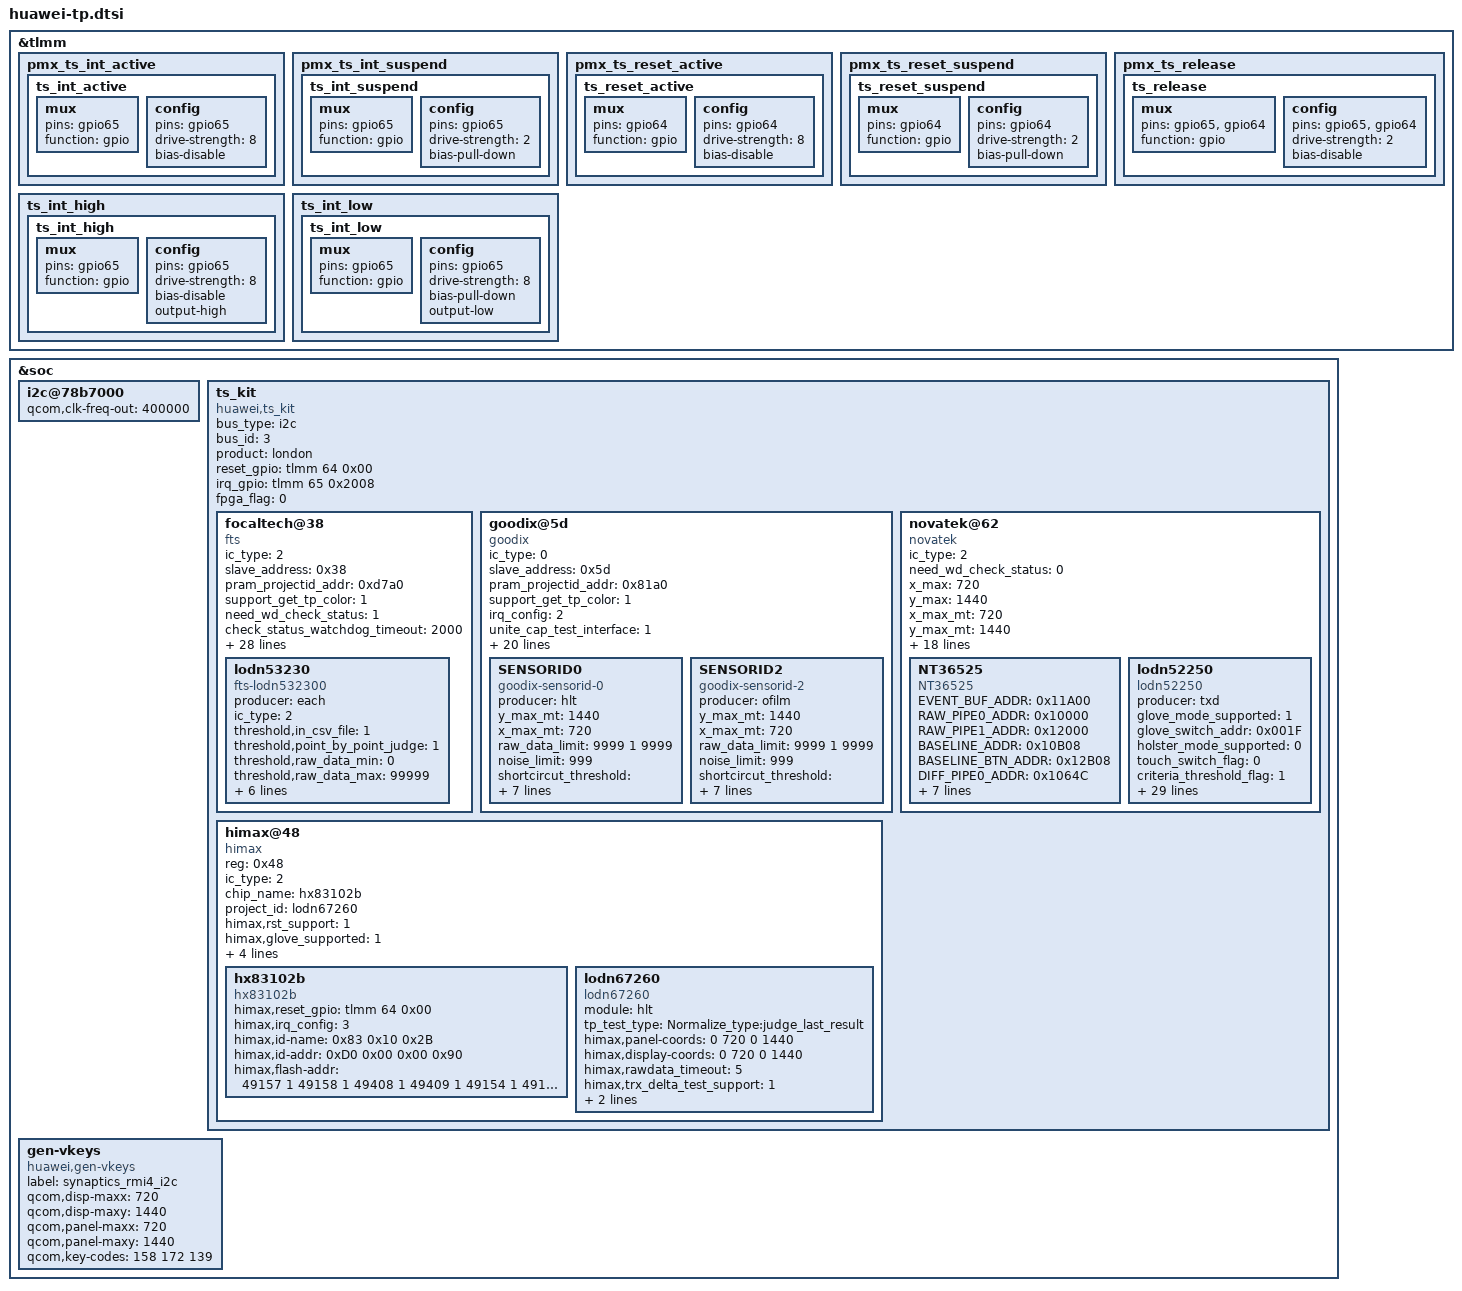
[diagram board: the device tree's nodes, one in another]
/* touch panel config */
&tlmm {
		/* add pingrp for touchscreen */
		pmx_ts_int_active {
			ts_int_active: ts_int_active {
				mux {
					pins = "gpio65";
					function = "gpio";
				};

				config {
					pins = "gpio65";
					drive-strength = <8>;
					bias-disable;
				};
			};
		};

		pmx_ts_int_suspend {
			ts_int_suspend: ts_int_suspend {
				mux {
					pins = "gpio65";
					function = "gpio";
				};

				config {
					pins = "gpio65";
					drive-strength = <2>;
					bias-pull-down;
				};
			};
		};

		pmx_ts_reset_active {
			ts_reset_active: ts_reset_active {
				mux {
					pins = "gpio64";
					function = "gpio";
				};

				config {
					pins = "gpio64";
					drive-strength = <8>;
					bias-disable;
				};
			};
		};

		pmx_ts_reset_suspend {
			ts_reset_suspend: ts_reset_suspend {
				mux {
					pins = "gpio64";
					function = "gpio";
				};

				config {
					pins = "gpio64";
					drive-strength = <2>;
					bias-pull-down;
				};
			};
		};

		pmx_ts_release {
			ts_release: ts_release {
				mux {
					pins = "gpio65", "gpio64";
					function = "gpio";
				};

				config {
					pins = "gpio65", "gpio64";
					drive-strength = <2>;
					bias-disable;
				};
			};
		};
		ts_int_high {
			ts_int_high: ts_int_high {
				mux {
					pins = "gpio65";
					function = "gpio";
				};

				config {
					pins = "gpio65";
					drive-strength = <8>;
					bias-disable;
					output-high;
				};
			};
		};
		ts_int_low {
			ts_int_low: ts_int_low {
				mux {
					pins = "gpio65";
					function = "gpio";
				};

				config {
					pins = "gpio65";
					drive-strength = <8>;
					bias-pull-down;
					output-low;
				};
			};
		};
};

&soc {
	i2c@78b7000{
		status = "ok";
		#address-cells = <1>;
		#size-cells = <0>;
		qcom,clk-freq-out = <400000>;
	};
	ts_kit {
		#address-cells = <1>;
		#size-cells = <0>;
		compatible = "huawei,ts_kit";
		bus_type = "i2c";
		bus_id = <3>;
		product = "london";
		reset_gpio = <&tlmm 64 0x00>;
		irq_gpio = <&tlmm 65 0x2008>;
		fpga_flag = <0>;
		focaltech@38 {
			compatible = "fts";
			ic_type = <2>;
			slave_address = <0x38>;
			pram_projectid_addr = <0xd7a0>;
			support_get_tp_color = <1>;
			need_wd_check_status = <1>;
			check_status_watchdog_timeout = <2000>;
			x_max = <720>;
			y_max = <1440>;
			x_max_mt = <720>;
			y_max_mt = <1440>;
			unite_cap_test_interface =<1>;
			report_rate_test =<0>;
			vci_gpio_type = <0>;
			vci_regulator_type = <1>;
			vddio_gpio_type = <0>;
			vddio_regulator_type = <1>;
			chip_id = <0x87>;
			hard_reset_delay = <200>;
			erase_min_delay = <1350>;
			calc_crc_delay = <300>;
			reboot_delay = <300>;
			erase_query_delay = <50>;
			write_flash_query_times = <30>;
			read_ecc_query_times = <100>;
			erase_flash_query_times = <15>;
			upgrade_loop_times = <5>;
			glove_supported = <1>;
			glove_switch_addr = <0xC0>;
			holster_switch_addr = <0xC1>;
			gesture_supported = <1>;
			irq_config = <3>;
			algo_id = <1>;
			is_in_cell = <0>;
			only_open_once_captest_threshold = <1>;
			lodn53230 {
				producer = "each";
				ic_type = <2>;
				compatible = "fts-lodn532300";
				threshold,in_csv_file = <1>;
				threshold,point_by_point_judge = <1>;
				threshold,raw_data_min = <0>;
				threshold,raw_data_max = <99999>;
				threshold,cb_test_min = <0>;
				threshold,cb_test_max = <9999>;
				threshold,scap_raw_data_min = <0>;
				threshold,scap_raw_data_max = <90000>;
				threshold,short_circuit_min = <0>;
				//threshold,open_test_cb_min = <100>;
				threshold,lcd_noise_max = <100>;
			};

		};
		goodix@5d {
			compatible = "goodix";
			ic_type = <0>;
			slave_address = <0x5d>;
			pram_projectid_addr = <0x81a0>;
			support_get_tp_color = <1>;
			irq_config = <2>;
			unite_cap_test_interface =<1>;
			algo_id = <2>;
			x_max = <720>;
			y_max = <1440>;
			x_max_mt = <720>;
			y_max_mt = <1440>;
			product_id = "GT917D";
			tools_support;
			huawei,test_capacitance_via_csvfile = <1>;
			huawei,csvfile_use_product_system = <1>;
			only_open_once_captest_threshold = <1>;
			need_wd_check_status = <1>;
			check_status_watchdog_timeout = <2000>;
			roi_data_size = <7 7>;
			gesture_supported = <1>;
			tp_test_type = "Normalize_type:judge_last_result";
			pinctrl-names = "pmx_ts_active","pmx_ts_suspend","pmx_ts_release","ts_int_high","ts_int_low";
			pinctrl-0 = <&ts_int_active &ts_reset_active>;
			pinctrl-1 = <&ts_int_suspend &ts_reset_suspend>;
			pinctrl-2 = <&ts_release>;
			pinctrl-3 = <&ts_int_high>;
			pinctrl-4 = <&ts_int_low>;
			SENSORID0 {
				compatible = "goodix-sensorid-0";
				producer = "hlt";
				y_max_mt = <1440>;
				x_max_mt = <720>;
				raw_data_limit = <9999 1 9999>;     /*rawdata-max*/
				noise_limit = <999>;
				shortcircut_threshold = <10 100 100 100 150 150 28>;
				normal_config = [
				4E D0 02 A0 05 0A FC 32 11 8F 2F
				0F 5F 4B 03 05 00 00 60 62 01 12
				05 16 19 1F 14 C7 27 EE 3C 3E B8
				08 B8 08 00 C3 33 91 00 00 00 00
				00 02 C0 08 0A 00 1A 28 50 8A 90
				54 19 28 00 04 AA 2A 00 97 31 00
				8A 38 00 7E 41 00 75 4A 00 75 00
				00 00 00 00 00 00 00 00 00 46 43
				00 00 00 00 00 00 00 02 00 00 0F
				32 00 03 00 00 32 05 55 00 00 00
				00 41 0D 00 01 02 03 04 05 06 07
				08 09 0A 0B 0C 1B 1A 19 18 17 16
				15 14 13 12 11 10 0F 0E FF FF 00
				02 04 05 06 08 0A 1E 1F 20 22 24
				29 2A FF FF FF 8C 31 3C 3C 00 8C
				70 12 00 32 4B 5A 19 1E 3C 0F 00
				06 66 66 0F 10 8B 84 85 00 00 00
				00 00 00 00 00 00 00 00 00 32 2D
				00 00 0F 14 00 37 5A 00 78 78 95
				00 55 00 41 43 E0 00 5A 32 08 00
				1E 03 00 00 00 00 1F 01];

				glove_config = [];
				holster_config = [];
				tptest_config = [
				00 D0 02 A0 05 05 3C 48 01 08
				28 0F 5A 46 05 05 00 00 00 00
				00 00 00 17 19 1E 14 87 27 EE
				96 98 D3 07 00 00 00 B9 32 11
				00 00 00 00 00 03 00 10 C8 00
				43 1E 50 94 10 03 07 28 00 04
				A3 21 00 8A 28 00 74 31 00 64
				3B 00 55 48 00 56 00 00 00 00
				00 00 00 00 00 00 00 00 00 00
				00 00 00 00 FF 7F 00 55 00 00
				00 00 00 00 00 01 46 00 00 00
				00 32 0D 00 01 02 03 04 05 06
				07 08 09 0A 0B 0C 1B 1A 19 18
				17 16 15 14 13 12 11 10 0F 0E
				FF FF 00 02 04 05 06 08 0A 1E
				1F 20 22 24 29 2A FF FF FF 00
				00 00 00 00 00 00 00 00 00 00
				00 00 00 00 00 00 00 00 00 00
				00 00 00 00 00 00 00 00 00 00
				00 00 00 00 00 00 00 00 00 00
				00 00 00 00 00 00 00 00 00 00
				00 00 00 00 00 00 00 00 00 00
				00 00 00 00 00 00 27 01];
			};
                        SENSORID2 {
				compatible = "goodix-sensorid-2";
				producer = "ofilm";
				y_max_mt = <1440>;
				x_max_mt = <720>;
				raw_data_limit = <9999 1 9999>;     /*rawdata-max*/
				noise_limit = <999>;
				shortcircut_threshold = <10 100 100 100 150 150 28>;
				normal_config = [
				4E D0 02 A0 05 0A FC 32 11 8F 2F
				0F 5F 50 03 05 00 00 60 62 02 01
				05 16 19 1F 14 C7 27 EE 3E 40 B8
				08 B8 08 00 C3 23 91 00 00 00 00
				00 02 C0 08 0A 00 1B 28 50 8A 90
				64 19 28 00 04 A9 2A 00 96 31 00
				89 38 00 7C 41 00 72 4A 00 72 00
				00 00 00 00 00 00 00 00 00 46 03
				00 00 00 00 00 00 00 02 00 00 0F
				32 00 03 00 00 32 06 4B 00 00 00
				00 41 04 13 00 1B 1A 19 18 17 16
				15 14 01 02 03 10 0F 0E 0D 0C 11
				12 0B 0A 09 08 07 06 05 FF FF 00
				02 04 05 06 08 0A 1E 1F 20 22 24
				29 2A FF FF FF 8C 31 3C 3C 00 8C
				70 12 00 32 4B 5A 19 1E 4B 00 00
				06 66 66 0F 10 8B 84 85 00 00 00
				00 00 00 00 00 00 00 00 00 32 28
				00 00 0F 14 00 37 53 00 78 78 95
				00 55 00 3C 43 E0 00 5A 32 08 00
				1E 03 00 00 00 00 8A 01];

				glove_config = [];
				holster_config = [];
				tptest_config = [
				00 D0 02 A0 05 0A 08 00 01 0F
				28 0F 82 64 03 05 00 00 00 00
				00 00 00 00 00 00 00 87 27 EE
				4C 4E D9 0B 00 00 00 01 03 1D
				00 00 00 00 00 00 00 00 00 00
				00 00 00 00 00 00 00 00 00 00
				00 00 00 00 00 00 00 00 00 00
				00 00 00 00 00 00 00 00 00 00
				00 00 00 00 00 00 00 00 00 00
				00 00 00 00 00 00 00 00 00 00
				00 00 00 00 00 00 00 00 00 00
				00 00 04 13 00 1B 1A 19 18 17
				16 15 14 01 02 03 10 0F 0E 0D
				0C 11 12 0B 0A 09 08 07 06 05
				FF FF 00 02 04 05 06 08 0A 1E
				1F 20 22 24 29 2A FF FF FF 00
				00 00 00 00 00 00 00 00 00 00
				00 00 00 00 00 00 00 00 00 00
				00 00 00 00 00 00 00 00 00 00
				00 00 00 00 00 00 00 00 00 00
				00 00 00 00 00 00 00 00 00 00
				00 00 00 00 00 00 00 00 00 00
				00 00 00 00 00 00 79 01];
			};
		};
		novatek@62 {
			compatible = "novatek";
			ic_type = <2>;
			need_wd_check_status = <0>;
			x_max = <720>;
			y_max = <1440>;
			x_max_mt = <720>;
			y_max_mt = <1440>;
			vci_gpio_type = <0>;
			vci_regulator_type = <1>;
			vddio_gpio_type = <0>;
			vddio_regulator_type = <1>;
			slave_address = <0x62>;
			power_sleep_mode = <1>;
			pinctrl-names = "default","idle";
			pinctrl-0 = <&ts_int_active &ts_reset_active>;
			pinctrl-1 = <&ts_int_suspend &ts_reset_suspend>;
			irq_config = <3>;
			algo_id = <1>;
			noise_test_frame = <10>;
			open_test_by_fw = <1>;
			nvt_chip_id_partone = <0x03>;
			nvt_chip_id_parttwo = <0x65>;
			nvt_chip_id_partthree = <0x25>;
			project_id_flash_address = <0x1E000>;
			gesture_supported = <1>;
			gesture_module = <1>;
			NT36525 {
				compatible = "NT36525";
				EVENT_BUF_ADDR           = <0x11A00>;
				RAW_PIPE0_ADDR           = <0x10000>;
				RAW_PIPE1_ADDR           = <0x12000>;
				BASELINE_ADDR            = <0x10B08>;
				BASELINE_BTN_ADDR        = <0x12B08>;
				DIFF_PIPE0_ADDR          = <0x1064C>;
				DIFF_PIPE1_ADDR          = <0x1264C>;
				RAW_BTN_PIPE0_ADDR       = <0x10634>;
				RAW_BTN_PIPE1_ADDR       = <0x12634>;
				DIFF_BTN_PIPE0_ADDR      = <0x10AFC>;
				DIFF_BTN_PIPE1_ADDR      = <0x12AFC>;
				READ_FLASH_CHECKSUM_ADDR = <0x14000>;
				RW_FLASH_DATA_ADDR       = <0x14002>;
			};
			lodn52250 {
				producer = "txd";
				compatible = "lodn52250";
				glove_mode_supported = <1>;
				glove_switch_addr = <0x001F>;
				holster_mode_supported = <0>;
				touch_switch_flag = <0>;
				criteria_threshold_flag = <1>;
				NvtTddi_X_Channel = <18>;
				NvtTddi_Y_Channel = <32>;
				PS_Config_Lmt_FW_CC_P = <99999>;
				PS_Config_Lmt_FW_CC_N = <0>;
				PS_Config_Lmt_FW_Diff_P = <99999>;
				PS_Config_Lmt_FW_Diff_N = <0xFFFFFFC0>;
				PS_Config_Lmt_Short_Rawdata_P = <99999>;
				PS_Config_Lmt_Short_Rawdata_N = <0>;
				mADCOper_Cnt = <2>;
				huawei,csvfile_use_system=<2>;
				huawei,test_capacitance_via_csvfile=<1>;
				tp_cap_test_type = "Normalize_type:judge_last_result";
				PS_Config_Lmt_FW_Rawdata_P =
					<99999 99999 99999 99999 99999 99999 99999 99999 99999 99999 99999 99999 99999 99999 99999 99999 99999 99999
					99999 99999 99999 99999 99999 99999 99999 99999 99999 99999 99999 99999 99999 99999 99999 99999 99999 99999
					99999 99999 99999 99999 99999 99999 99999 99999 99999 99999 99999 99999 99999 99999 99999 99999 99999 99999
					99999 99999 99999 99999 99999 99999 99999 99999 99999 99999 99999 99999 99999 99999 99999 99999 99999 99999
					99999 99999 99999 99999 99999 99999 99999 99999 99999 99999 99999 99999 99999 99999 99999 99999 99999 99999
					99999 99999 99999 99999 99999 99999 99999 99999 99999 99999 99999 99999 99999 99999 99999 99999 99999 99999
					99999 99999 99999 99999 99999 99999 99999 99999 99999 99999 99999 99999 99999 99999 99999 99999 99999 99999
					99999 99999 99999 99999 99999 99999 99999 99999 99999 99999 99999 99999 99999 99999 99999 99999 99999 99999
					99999 99999 99999 99999 99999 99999 99999 99999 99999 99999 99999 99999 99999 99999 99999 99999 99999 99999
					99999 99999 99999 99999 99999 99999 99999 99999 99999 99999 99999 99999 99999 99999 99999 99999 99999 99999
					99999 99999 99999 99999 99999 99999 99999 99999 99999 99999 99999 99999 99999 99999 99999 99999 99999 99999
					99999 99999 99999 99999 99999 99999 99999 99999 99999 99999 99999 99999 99999 99999 99999 99999 99999 99999
					99999 99999 99999 99999 99999 99999 99999 99999 99999 99999 99999 99999 99999 99999 99999 99999 99999 99999
					99999 99999 99999 99999 99999 99999 99999 99999 99999 99999 99999 99999 99999 99999 99999 99999 99999 99999
					99999 99999 99999 99999 99999 99999 99999 99999 99999 99999 99999 99999 99999 99999 99999 99999 99999 99999
					99999 99999 99999 99999 99999 99999 99999 99999 99999 99999 99999 99999 99999 99999 99999 99999 99999 99999
					99999 99999 99999 99999 99999 99999 99999 99999 99999 99999 99999 99999 99999 99999 99999 99999 99999 99999
					99999 99999 99999 99999 99999 99999 99999 99999 99999 99999 99999 99999 99999 99999 99999 99999 99999 99999
					99999 99999 99999 99999 99999 99999 99999 99999 99999 99999 99999 99999 99999 99999 99999 99999 99999 99999
					99999 99999 99999 99999 99999 99999 99999 99999 99999 99999 99999 99999 99999 99999 99999 99999 99999 99999
					99999 99999 99999 99999 99999 99999 99999 99999 99999 99999 99999 99999 99999 99999 99999 99999 99999 99999
					99999 99999 99999 99999 99999 99999 99999 99999 99999 99999 99999 99999 99999 99999 99999 99999 99999 99999
					99999 99999 99999 99999 99999 99999 99999 99999 99999 99999 99999 99999 99999 99999 99999 99999 99999 99999
					99999 99999 99999 99999 99999 99999 99999 99999 99999 99999 99999 99999 99999 99999 99999 99999 99999 99999
					99999 99999 99999 99999 99999 99999 99999 99999 99999 99999 99999 99999 99999 99999 99999 99999 99999 99999
					99999 99999 99999 99999 99999 99999 99999 99999 99999 99999 99999 99999 99999 99999 99999 99999 99999 99999
					99999 99999 99999 99999 99999 99999 99999 99999 99999 99999 99999 99999 99999 99999 99999 99999 99999 99999
					99999 99999 99999 99999 99999 99999 99999 99999 99999 99999 99999 99999 99999 99999 99999 99999 99999 99999
					99999 99999 99999 99999 99999 99999 99999 99999 99999 99999 99999 99999 99999 99999 99999 99999 99999 99999
					99999 99999 99999 99999 99999 99999 99999 99999 99999 99999 99999 99999 99999 99999 99999 99999 99999 99999
					99999 99999 99999 99999 99999 99999 99999 99999 99999 99999 99999 99999 99999 99999 99999 99999 99999 99999
					99999 99999 99999 99999 99999 99999 99999 99999 99999 99999 99999 99999 99999 99999 99999 99999 99999 99999>;
				PS_Config_Lmt_FW_Rawdata_N =
					<0 0 0 0 0 0 0 0 0 0 0 0 0 0 0 0 0 0
					0 0 0 0 0 0 0 0 0 0 0 0 0 0 0 0 0 0
					0 0 0 0 0 0 0 0 0 0 0 0 0 0 0 0 0 0
					0 0 0 0 0 0 0 0 0 0 0 0 0 0 0 0 0 0
					0 0 0 0 0 0 0 0 0 0 0 0 0 0 0 0 0 0
					0 0 0 0 0 0 0 0 0 0 0 0 0 0 0 0 0 0
					0 0 0 0 0 0 0 0 0 0 0 0 0 0 0 0 0 0
					0 0 0 0 0 0 0 0 0 0 0 0 0 0 0 0 0 0
					0 0 0 0 0 0 0 0 0 0 0 0 0 0 0 0 0 0
					0 0 0 0 0 0 0 0 0 0 0 0 0 0 0 0 0 0
					0 0 0 0 0 0 0 0 0 0 0 0 0 0 0 0 0 0
					0 0 0 0 0 0 0 0 0 0 0 0 0 0 0 0 0 0
					0 0 0 0 0 0 0 0 0 0 0 0 0 0 0 0 0 0
					0 0 0 0 0 0 0 0 0 0 0 0 0 0 0 0 0 0
					0 0 0 0 0 0 0 0 0 0 0 0 0 0 0 0 0 0
					0 0 0 0 0 0 0 0 0 0 0 0 0 0 0 0 0 0
					0 0 0 0 0 0 0 0 0 0 0 0 0 0 0 0 0 0
					0 0 0 0 0 0 0 0 0 0 0 0 0 0 0 0 0 0
					0 0 0 0 0 0 0 0 0 0 0 0 0 0 0 0 0 0
					0 0 0 0 0 0 0 0 0 0 0 0 0 0 0 0 0 0
					0 0 0 0 0 0 0 0 0 0 0 0 0 0 0 0 0 0
					0 0 0 0 0 0 0 0 0 0 0 0 0 0 0 0 0 0
					0 0 0 0 0 0 0 0 0 0 0 0 0 0 0 0 0 0
					0 0 0 0 0 0 0 0 0 0 0 0 0 0 0 0 0 0
					0 0 0 0 0 0 0 0 0 0 0 0 0 0 0 0 0 0
					0 0 0 0 0 0 0 0 0 0 0 0 0 0 0 0 0 0
					0 0 0 0 0 0 0 0 0 0 0 0 0 0 0 0 0 0
					0 0 0 0 0 0 0 0 0 0 0 0 0 0 0 0 0 0
					0 0 0 0 0 0 0 0 0 0 0 0 0 0 0 0 0 0
					0 0 0 0 0 0 0 0 0 0 0 0 0 0 0 0 0 0
					0 0 0 0 0 0 0 0 0 0 0 0 0 0 0 0 0 0
					0 0 0 0 0 0 0 0 0 0 0 0 0 0 0 0 0 0>;
				PS_Config_Lmt_FW_Rawdata_X_Delta =
					<9999 9999 9999 9999 9999 9999 9999 9999 9999 9999 9999 9999 9999 9999 9999 9999 9999
					9999 9999 9999 9999 9999 9999 9999 9999 9999 9999 9999 9999 9999 9999 9999 9999 9999
					9999 9999 9999 9999 9999 9999 9999 9999 9999 9999 9999 9999 9999 9999 9999 9999 9999
					9999 9999 9999 9999 9999 9999 9999 9999 9999 9999 9999 9999 9999 9999 9999 9999 9999
					9999 9999 9999 9999 9999 9999 9999 9999 9999 9999 9999 9999 9999 9999 9999 9999 9999
					9999 9999 9999 9999 9999 9999 9999 9999 9999 9999 9999 9999 9999 9999 9999 9999 9999
					9999 9999 9999 9999 9999 9999 9999 9999 9999 9999 9999 9999 9999 9999 9999 9999 9999
					9999 9999 9999 9999 9999 9999 9999 9999 9999 9999 9999 9999 9999 9999 9999 9999 9999
					9999 9999 9999 9999 9999 9999 9999 9999 9999 9999 9999 9999 9999 9999 9999 9999 9999
					9999 9999 9999 9999 9999 9999 9999 9999 9999 9999 9999 9999 9999 9999 9999 9999 9999
					9999 9999 9999 9999 9999 9999 9999 9999 9999 9999 9999 9999 9999 9999 9999 9999 9999
					9999 9999 9999 9999 9999 9999 9999 9999 9999 9999 9999 9999 9999 9999 9999 9999 9999
					9999 9999 9999 9999 9999 9999 9999 9999 9999 9999 9999 9999 9999 9999 9999 9999 9999
					9999 9999 9999 9999 9999 9999 9999 9999 9999 9999 9999 9999 9999 9999 9999 9999 9999
					9999 9999 9999 9999 9999 9999 9999 9999 9999 9999 9999 9999 9999 9999 9999 9999 9999
					9999 9999 9999 9999 9999 9999 9999 9999 9999 9999 9999 9999 9999 9999 9999 9999 9999
					9999 9999 9999 9999 9999 9999 9999 9999 9999 9999 9999 9999 9999 9999 9999 9999 9999
					9999 9999 9999 9999 9999 9999 9999 9999 9999 9999 9999 9999 9999 9999 9999 9999 9999
					9999 9999 9999 9999 9999 9999 9999 9999 9999 9999 9999 9999 9999 9999 9999 9999 9999
					9999 9999 9999 9999 9999 9999 9999 9999 9999 9999 9999 9999 9999 9999 9999 9999 9999
					9999 9999 9999 9999 9999 9999 9999 9999 9999 9999 9999 9999 9999 9999 9999 9999 9999
					9999 9999 9999 9999 9999 9999 9999 9999 9999 9999 9999 9999 9999 9999 9999 9999 9999
					9999 9999 9999 9999 9999 9999 9999 9999 9999 9999 9999 9999 9999 9999 9999 9999 9999
					9999 9999 9999 9999 9999 9999 9999 9999 9999 9999 9999 9999 9999 9999 9999 9999 9999
					9999 9999 9999 9999 9999 9999 9999 9999 9999 9999 9999 9999 9999 9999 9999 9999 9999
					9999 9999 9999 9999 9999 9999 9999 9999 9999 9999 9999 9999 9999 9999 9999 9999 9999
					9999 9999 9999 9999 9999 9999 9999 9999 9999 9999 9999 9999 9999 9999 9999 9999 9999
					9999 9999 9999 9999 9999 9999 9999 9999 9999 9999 9999 9999 9999 9999 9999 9999 9999
					9999 9999 9999 9999 9999 9999 9999 9999 9999 9999 9999 9999 9999 9999 9999 9999 9999
					9999 9999 9999 9999 9999 9999 9999 9999 9999 9999 9999 9999 9999 9999 9999 9999 9999
					9999 9999 9999 9999 9999 9999 9999 9999 9999 9999 9999 9999 9999 9999 9999 9999 9999
					9999 9999 9999 9999 9999 9999 9999 9999 9999 9999 9999 9999 9999 9999 9999 9999 9999>;
				PS_Config_Lmt_FW_Rawdata_Y_Delta =
					<9999 9999 9999 9999 9999 9999 9999 9999 9999 9999 9999 9999 9999 9999 9999 9999 9999 9999
					9999 9999 9999 9999 9999 9999 9999 9999 9999 9999 9999 9999 9999 9999 9999 9999 9999 9999
					9999 9999 9999 9999 9999 9999 9999 9999 9999 9999 9999 9999 9999 9999 9999 9999 9999 9999
					9999 9999 9999 9999 9999 9999 9999 9999 9999 9999 9999 9999 9999 9999 9999 9999 9999 9999
					9999 9999 9999 9999 9999 9999 9999 9999 9999 9999 9999 9999 9999 9999 9999 9999 9999 9999
					9999 9999 9999 9999 9999 9999 9999 9999 9999 9999 9999 9999 9999 9999 9999 9999 9999 9999
					9999 9999 9999 9999 9999 9999 9999 9999 9999 9999 9999 9999 9999 9999 9999 9999 9999 9999
					9999 9999 9999 9999 9999 9999 9999 9999 9999 9999 9999 9999 9999 9999 9999 9999 9999 9999
					9999 9999 9999 9999 9999 9999 9999 9999 9999 9999 9999 9999 9999 9999 9999 9999 9999 9999
					9999 9999 9999 9999 9999 9999 9999 9999 9999 9999 9999 9999 9999 9999 9999 9999 9999 9999
					9999 9999 9999 9999 9999 9999 9999 9999 9999 9999 9999 9999 9999 9999 9999 9999 9999 9999
					9999 9999 9999 9999 9999 9999 9999 9999 9999 9999 9999 9999 9999 9999 9999 9999 9999 9999
					9999 9999 9999 9999 9999 9999 9999 9999 9999 9999 9999 9999 9999 9999 9999 9999 9999 9999
					9999 9999 9999 9999 9999 9999 9999 9999 9999 9999 9999 9999 9999 9999 9999 9999 9999 9999
					9999 9999 9999 9999 9999 9999 9999 9999 9999 9999 9999 9999 9999 9999 9999 9999 9999 9999
					9999 9999 9999 9999 9999 9999 9999 9999 9999 9999 9999 9999 9999 9999 9999 9999 9999 9999
					9999 9999 9999 9999 9999 9999 9999 9999 9999 9999 9999 9999 9999 9999 9999 9999 9999 9999
					9999 9999 9999 9999 9999 9999 9999 9999 9999 9999 9999 9999 9999 9999 9999 9999 9999 9999
					9999 9999 9999 9999 9999 9999 9999 9999 9999 9999 9999 9999 9999 9999 9999 9999 9999 9999
					9999 9999 9999 9999 9999 9999 9999 9999 9999 9999 9999 9999 9999 9999 9999 9999 9999 9999
					9999 9999 9999 9999 9999 9999 9999 9999 9999 9999 9999 9999 9999 9999 9999 9999 9999 9999
					9999 9999 9999 9999 9999 9999 9999 9999 9999 9999 9999 9999 9999 9999 9999 9999 9999 9999
					9999 9999 9999 9999 9999 9999 9999 9999 9999 9999 9999 9999 9999 9999 9999 9999 9999 9999
					9999 9999 9999 9999 9999 9999 9999 9999 9999 9999 9999 9999 9999 9999 9999 9999 9999 9999
					9999 9999 9999 9999 9999 9999 9999 9999 9999 9999 9999 9999 9999 9999 9999 9999 9999 9999
					9999 9999 9999 9999 9999 9999 9999 9999 9999 9999 9999 9999 9999 9999 9999 9999 9999 9999
					9999 9999 9999 9999 9999 9999 9999 9999 9999 9999 9999 9999 9999 9999 9999 9999 9999 9999
					9999 9999 9999 9999 9999 9999 9999 9999 9999 9999 9999 9999 9999 9999 9999 9999 9999 9999
					9999 9999 9999 9999 9999 9999 9999 9999 9999 9999 9999 9999 9999 9999 9999 9999 9999 9999
					9999 9999 9999 9999 9999 9999 9999 9999 9999 9999 9999 9999 9999 9999 9999 9999 9999 9999
					9999 9999 9999 9999 9999 9999 9999 9999 9999 9999 9999 9999 9999 9999 9999 9999 9999 9999>;
				PS_Config_Lmt_Open_Rawdata_P_A =
					<99999 99999 99999 99999 99999 99999 99999 99999 99999 99999 99999 99999 99999 99999 99999 99999 99999 99999
					99999 99999 99999 99999 99999 99999 99999 99999 99999 99999 99999 99999 99999 99999 99999 99999 99999 99999
					99999 99999 99999 99999 99999 99999 99999 99999 99999 99999 99999 99999 99999 99999 99999 99999 99999 99999
					99999 99999 99999 99999 99999 99999 99999 99999 99999 99999 99999 99999 99999 99999 99999 99999 99999 99999
					99999 99999 99999 99999 99999 99999 99999 99999 99999 99999 99999 99999 99999 99999 99999 99999 99999 99999
					99999 99999 99999 99999 99999 99999 99999 99999 99999 99999 99999 99999 99999 99999 99999 99999 99999 99999
					99999 99999 99999 99999 99999 99999 99999 99999 99999 99999 99999 99999 99999 99999 99999 99999 99999 99999
					99999 99999 99999 99999 99999 99999 99999 99999 99999 99999 99999 99999 99999 99999 99999 99999 99999 99999
					99999 99999 99999 99999 99999 99999 99999 99999 99999 99999 99999 99999 99999 99999 99999 99999 99999 99999
					99999 99999 99999 99999 99999 99999 99999 99999 99999 99999 99999 99999 99999 99999 99999 99999 99999 99999
					99999 99999 99999 99999 99999 99999 99999 99999 99999 99999 99999 99999 99999 99999 99999 99999 99999 99999
					99999 99999 99999 99999 99999 99999 99999 99999 99999 99999 99999 99999 99999 99999 99999 99999 99999 99999
					99999 99999 99999 99999 99999 99999 99999 99999 99999 99999 99999 99999 99999 99999 99999 99999 99999 99999
					99999 99999 99999 99999 99999 99999 99999 99999 99999 99999 99999 99999 99999 99999 99999 99999 99999 99999
					99999 99999 99999 99999 99999 99999 99999 99999 99999 99999 99999 99999 99999 99999 99999 99999 99999 99999
					99999 99999 99999 99999 99999 99999 99999 99999 99999 99999 99999 99999 99999 99999 99999 99999 99999 99999
					99999 99999 99999 99999 99999 99999 99999 99999 99999 99999 99999 99999 99999 99999 99999 99999 99999 99999
					99999 99999 99999 99999 99999 99999 99999 99999 99999 99999 99999 99999 99999 99999 99999 99999 99999 99999
					99999 99999 99999 99999 99999 99999 99999 99999 99999 99999 99999 99999 99999 99999 99999 99999 99999 99999
					99999 99999 99999 99999 99999 99999 99999 99999 99999 99999 99999 99999 99999 99999 99999 99999 99999 99999
					99999 99999 99999 99999 99999 99999 99999 99999 99999 99999 99999 99999 99999 99999 99999 99999 99999 99999
					99999 99999 99999 99999 99999 99999 99999 99999 99999 99999 99999 99999 99999 99999 99999 99999 99999 99999
					99999 99999 99999 99999 99999 99999 99999 99999 99999 99999 99999 99999 99999 99999 99999 99999 99999 99999
					99999 99999 99999 99999 99999 99999 99999 99999 99999 99999 99999 99999 99999 99999 99999 99999 99999 99999
					99999 99999 99999 99999 99999 99999 99999 99999 99999 99999 99999 99999 99999 99999 99999 99999 99999 99999
					99999 99999 99999 99999 99999 99999 99999 99999 99999 99999 99999 99999 99999 99999 99999 99999 99999 99999
					99999 99999 99999 99999 99999 99999 99999 99999 99999 99999 99999 99999 99999 99999 99999 99999 99999 99999
					99999 99999 99999 99999 99999 99999 99999 99999 99999 99999 99999 99999 99999 99999 99999 99999 99999 99999
					99999 99999 99999 99999 99999 99999 99999 99999 99999 99999 99999 99999 99999 99999 99999 99999 99999 99999
					99999 99999 99999 99999 99999 99999 99999 99999 99999 99999 99999 99999 99999 99999 99999 99999 99999 99999
					99999 99999 99999 99999 99999 99999 99999 99999 99999 99999 99999 99999 99999 99999 99999 99999 99999 99999
					99999 99999 99999 99999 99999 99999 99999 99999 99999 99999 99999 99999 99999 99999 99999 99999 99999 99999>;
				PS_Config_Lmt_Open_Rawdata_N_A =
					<0 0 0 0 0 0 0 0 0 0 0 0 0 0 0 0 0 0
					0 0 0 0 0 0 0 0 0 0 0 0 0 0 0 0 0 0
					0 0 0 0 0 0 0 0 0 0 0 0 0 0 0 0 0 0
					0 0 0 0 0 0 0 0 0 0 0 0 0 0 0 0 0 0
					0 0 0 0 0 0 0 0 0 0 0 0 0 0 0 0 0 0
					0 0 0 0 0 0 0 0 0 0 0 0 0 0 0 0 0 0
					0 0 0 0 0 0 0 0 0 0 0 0 0 0 0 0 0 0
					0 0 0 0 0 0 0 0 0 0 0 0 0 0 0 0 0 0
					0 0 0 0 0 0 0 0 0 0 0 0 0 0 0 0 0 0
					0 0 0 0 0 0 0 0 0 0 0 0 0 0 0 0 0 0
					0 0 0 0 0 0 0 0 0 0 0 0 0 0 0 0 0 0
					0 0 0 0 0 0 0 0 0 0 0 0 0 0 0 0 0 0
					0 0 0 0 0 0 0 0 0 0 0 0 0 0 0 0 0 0
					0 0 0 0 0 0 0 0 0 0 0 0 0 0 0 0 0 0
					0 0 0 0 0 0 0 0 0 0 0 0 0 0 0 0 0 0
					0 0 0 0 0 0 0 0 0 0 0 0 0 0 0 0 0 0
					0 0 0 0 0 0 0 0 0 0 0 0 0 0 0 0 0 0
					0 0 0 0 0 0 0 0 0 0 0 0 0 0 0 0 0 0
					0 0 0 0 0 0 0 0 0 0 0 0 0 0 0 0 0 0
					0 0 0 0 0 0 0 0 0 0 0 0 0 0 0 0 0 0
					0 0 0 0 0 0 0 0 0 0 0 0 0 0 0 0 0 0
					0 0 0 0 0 0 0 0 0 0 0 0 0 0 0 0 0 0
					0 0 0 0 0 0 0 0 0 0 0 0 0 0 0 0 0 0
					0 0 0 0 0 0 0 0 0 0 0 0 0 0 0 0 0 0
					0 0 0 0 0 0 0 0 0 0 0 0 0 0 0 0 0 0
					0 0 0 0 0 0 0 0 0 0 0 0 0 0 0 0 0 0
					0 0 0 0 0 0 0 0 0 0 0 0 0 0 0 0 0 0
					0 0 0 0 0 0 0 0 0 0 0 0 0 0 0 0 0 0
					0 0 0 0 0 0 0 0 0 0 0 0 0 0 0 0 0 0
					0 0 0 0 0 0 0 0 0 0 0 0 0 0 0 0 0 0
					0 0 0 0 0 0 0 0 0 0 0 0 0 0 0 0 0 0
					0 0 0 0 0 0 0 0 0 0 0 0 0 0 0 0 0 0>;
				NVT_TDDI_AIN_X = <17 16 15 14 13 12 11 10 9 8 7 6 5 4 3 2 1 0>;
				NVT_TDDI_AIN_Y = <31 30 29 28 27 26 25 24 23 22 21 20 19 18 17 16 15 14 13 12 11 10 9 8 7 6 5 4 3 2 1 0>;
			};
		};
		himax@48 {
	                status = "ok";
	                compatible = "himax";
	                reg = <0x48>;
	                ic_type = <2>;
			chip_name = "hx83102b";
			project_id = "lodn67260";
			himax,rst_support = <1>;
			himax,glove_supported = <1>;
			himax,gesture_supported = <1>;
			himax,re_send_cmd_support = <1>;			
			himax,panel-coords = <0 720 0 1440>;
			himax,display-coords = <0 720 0 1440>;
	                hx83102b{
				compatible = "hx83102b";
				himax,reset_gpio = <&tlmm 64 0x00>;
				himax,irq_config = <3>;/* 0 - LOW LEVEL  1 - HIGH LEVEL  2 - RAISE EDGE  3 - FALL EDGE*/
				himax,id-name = <0x83 0x10 0x2B>;/* 131 16 43 */
				himax,id-addr = <0xD0 0x00 0x00 0x90>; /*208 0 0 144 */
				himax,flash-addr = <49157 1 49158 1 49408 1 49409 1 49154 1 49155 1 49156 1>;/* ADDR LENTH */
			};
			lodn67260{
				compatible = "lodn67260";
				module = "hlt";
				tp_test_type = "Normalize_type:judge_last_result";
				himax,panel-coords = <0 720 0 1440>;
				himax,display-coords = <0 720 0 1440>;
				himax,rawdata_timeout = <5>;
				himax,trx_delta_test_support  = <1>;
				himax,test_capacitance_via_csvfile = <1>;
				himax,csvfile_use_system = <1>;	/*1 - PRODUCT   2 - ODM*/
			};
		};
	
	};
	/*To disable gen-vkeys.c probe,avoid generate kobject*/
	gen-vkeys {
		compatible = "huawei,gen-vkeys";
		label = "synaptics_rmi4_i2c";
		qcom,disp-maxx = <720>;
		qcom,disp-maxy = <1440>;
		qcom,panel-maxx = <720>;
		qcom,panel-maxy = <1440>;
		qcom,key-codes = <158 172 139>;
	};
};
